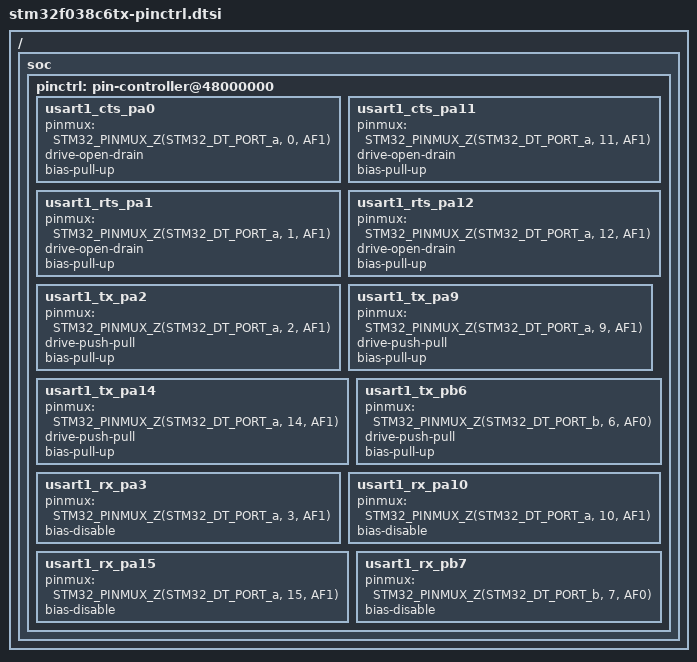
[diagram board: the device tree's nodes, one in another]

/*
 * NOTE: Autogenerated file using stm32_pinctrl_gen.py
 *
 * SPDX-License-Identifier: Apache-2.0
 */

#include <dt-bindings/pinctrl/stm32-pinctrl.h>

/ {
	soc {
		pinctrl: pin-controller@48000000 {
			/* UART_CTS */
			usart1_cts_pa0: usart1_cts_pa0 {
				pinmux = <STM32_PINMUX_Z(STM32_DT_PORT_a, 0, AF1)>;
				drive-open-drain;
				bias-pull-up;
			};

			usart1_cts_pa11: usart1_cts_pa11 {
				pinmux = <STM32_PINMUX_Z(STM32_DT_PORT_a, 11, AF1)>;
				drive-open-drain;
				bias-pull-up;
			};


			/* UART_RTS */
			usart1_rts_pa1: usart1_rts_pa1 {
				pinmux = <STM32_PINMUX_Z(STM32_DT_PORT_a, 1, AF1)>;
				drive-open-drain;
				bias-pull-up;
			};

			usart1_rts_pa12: usart1_rts_pa12 {
				pinmux = <STM32_PINMUX_Z(STM32_DT_PORT_a, 12, AF1)>;
				drive-open-drain;
				bias-pull-up;
			};


			/* UART_TX */
			usart1_tx_pa2: usart1_tx_pa2 {
				pinmux = <STM32_PINMUX_Z(STM32_DT_PORT_a, 2, AF1)>;
				drive-push-pull;
				bias-pull-up;
			};

			usart1_tx_pa9: usart1_tx_pa9 {
				pinmux = <STM32_PINMUX_Z(STM32_DT_PORT_a, 9, AF1)>;
				drive-push-pull;
				bias-pull-up;
			};

			usart1_tx_pa14: usart1_tx_pa14 {
				pinmux = <STM32_PINMUX_Z(STM32_DT_PORT_a, 14, AF1)>;
				drive-push-pull;
				bias-pull-up;
			};

			usart1_tx_pb6: usart1_tx_pb6 {
				pinmux = <STM32_PINMUX_Z(STM32_DT_PORT_b, 6, AF0)>;
				drive-push-pull;
				bias-pull-up;
			};


			/* UART_RX */
			usart1_rx_pa3: usart1_rx_pa3 {
				pinmux = <STM32_PINMUX_Z(STM32_DT_PORT_a, 3, AF1)>;
				bias-disable;
			};

			usart1_rx_pa10: usart1_rx_pa10 {
				pinmux = <STM32_PINMUX_Z(STM32_DT_PORT_a, 10, AF1)>;
				bias-disable;
			};

			usart1_rx_pa15: usart1_rx_pa15 {
				pinmux = <STM32_PINMUX_Z(STM32_DT_PORT_a, 15, AF1)>;
				bias-disable;
			};

			usart1_rx_pb7: usart1_rx_pb7 {
				pinmux = <STM32_PINMUX_Z(STM32_DT_PORT_b, 7, AF0)>;
				bias-disable;
			};

		};
	};
};
